# ATtiny2313 device description
Architecture: AVR8; Family: tinyAVR
Programming and debug interfaces: ISP, HVPP, debugWIRE
Registers are 8-bit, access not given, no defined reset value unless marked. A register's access mark holds for its fields unless they carry their own. Offsets are from the block's base; lines under a group give offsets from that group; [hi:lo] are bit positions; {n}, {i} and the like mark numbered series; 'fields as' and 'values as' point back to an identical list; <NAME> marks a mode.

## Ordering variants
ATtiny2313V-10PU: PDIP20, up to 10 MHz, -40 to 85 C, 1.8 to 5.5 V
ATtiny2313V-10SU, ATtiny2313V-10SUR: SOIC20, up to 10 MHz, -40 to 85 C, 1.8 to 5.5 V
ATtiny2313V-10MU, ATtiny2313V-10MUR: MLF20, up to 10 MHz, -40 to 85 C, 1.8 to 5.5 V
ATtiny2313-20PU: PDIP20, up to 20 MHz, -40 to 85 C, 2.7 to 5.5 V
ATtiny2313-20SU, ATtiny2313-20SUR: SOIC20, up to 20 MHz, -40 to 85 C, 2.7 to 5.5 V
ATtiny2313-20MU, ATtiny2313-20MUR: MLF20, up to 20 MHz, -40 to 85 C, 2.7 to 5.5 V

## Memory
prog space: start 0x0000 size 0x0800, little endian
  0x0000 FLASH size 0x0800 flash, rw, executable, page 0x20
signatures space: start 0 size 3, little endian
  0 SIGNATURES size 3 signatures, ro
fuses space: start 0 size 0x0003, little endian
  0 FUSES size 0x0003 fuses, rw
lockbits space: start 0 size 0x0001, little endian
  0 LOCKBITS size 0x0001 lockbits, rw
data space: start 0x0000 size 0x00e0, little endian
  0x0000 REGISTERS size 0x0020 regs
  0x0020 MAPPED_IO size 0x0040 io
  0x0060 IRAM size 0x0080 ram
eeprom space: start 0x0000 size 0x0080, little endian
  0x0000 EEPROM size 0x0080 eeprom, rw, page 0x04
io space: start 0x00 size 0x40, little endian
osccal space: start 0 size 2, little endian
  0 OSCCAL size 2 osccal, ro

## Peripheral instances (address, pins/pin function, parameters)
PORTB at 0x00 — I/O Port
PORTD at 0x00 — I/O Port
PORTA at 0x00 — I/O Port
TC0 at 0x00 — Timer/Counter, 8-bit
TC1 at 0x00 — Timer/Counter, 16-bit
WDT at 0x00 — Watchdog Timer
EXINT at 0x00 — External Interrupts
USART at 0x00
AC at 0x00 — Analog Comparator
EEPROM at 0x00
CPU at 0x00 — CPU Registers
  parameters: CORE_VERSION=V2, NEW_INSTRUCTIONS=lpm rd,z+
USI at 0x00 — Universal Serial Interface
FUSE at 0 in fuses — Fuses
LOCKBIT at 0 in lockbits — Lockbits

## Interrupts
0 RESET — External Reset, Power-on Reset and Watchdog Reset
1 INT0 — External Interrupt Request 0
2 INT1 — External Interrupt Request 1
3 TIMER1_CAPT — Timer/Counter1 Capture Event
4 TIMER1_COMPA — Timer/Counter1 Compare Match A
5 TIMER1_OVF — Timer/Counter1 Overflow
6 TIMER0_OVF — Timer/Counter0 Overflow
7 USART_RX — USART, Rx Complete
8 USART_UDRE — USART Data Register Empty
9 USART_TX — USART, Tx Complete
10 ANA_COMP — Analog Comparator
11 PCINT
12 TIMER1_COMPB
13 TIMER0_COMPA
14 TIMER0_COMPB
15 USI_START — USI Start Condition
16 USI_OVERFLOW
17 EEPROM_Ready
18 WDT_OVERFLOW — Watchdog Timer Overflow

## Properties
SIGNATURES: JTAGID=0x910A, SIGNATURE0=0x1e, SIGNATURE1=0x91, SIGNATURE2=0x0a
OCD: OCD_REVISION=0, OCD_DATAREG=0x1f, PROGBASE=0x0000

## LOCKBIT — Lockbits
Instances: LOCKBIT 0 in lockbits
0x00 LOCKBIT reset 0xFF
  [1:0] LB — Memory Lock
    0=PROG_VER_DISABLED (Further programming and verification disabled); 2=PROG_DISABLED (Further programming disabled); 3=NO_LOCK (No memory lock features enabled)

## PORTB — I/O Port
Instances: PORTB 0x00
0x36 PINB — Port B Input Pins
0x37 DDRB — Port B Data Direction Register
0x38 PORTB — Port B Data Register

## PORTD — I/O Port
Instances: PORTD 0x00
0x30 PIND bits used 6:0 — Input Pins, Port D
0x31 DDRD bits used 6:0 — Data Direction Register, Port D
0x32 PORTD bits used 6:0 — Data Register, Port D

## PORTA — I/O Port
Instances: PORTA 0x00
0x39 PINA bits used 2:0 — Port A Input Pins
0x3A DDRA bits used 2:0 — Port A Data Direction Register
0x3B PORTA bits used 2:0 — Port A Data Register

## TC0 (TC8 module) — Timer/Counter, 8-bit
Instances: TC0 0x00
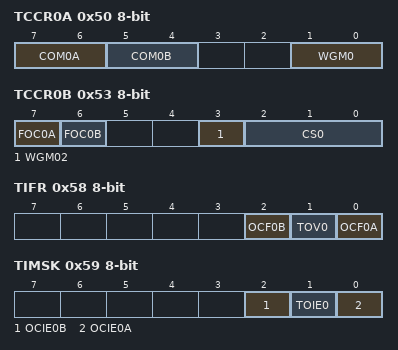
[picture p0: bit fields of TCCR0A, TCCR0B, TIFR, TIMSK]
0x50 TCCR0A — Timer/Counter Control Register A
  [7:6] COM0A — Compare Match Output A Mode
  [5:4] COM0B — Compare Match Output B Mode
  [1:0] WGM0 — Waveform Generation Mode
0x52 TCNT0 — Timer/Counter0
0x53 TCCR0B — Timer/Counter Control Register B
  [7] FOC0A — Force Output Compare B
  [6] FOC0B — Force Output Compare B
  [3] WGM02
  [2:0] CS0 — Clock Select
    0=NO_CLOCK_SOURCE_STOPPED; 1=RUNNING_NO_PRESCALING; 2=RUNNING_CLK_8; 3=RUNNING_CLK_64; 4=RUNNING_CLK_256; 5=RUNNING_CLK_1024; 6=RUNNING_EXTCLK_TN_FALLING_EDGE; 7=RUNNING_EXTCLK_TN_RISING_EDGE
0x56 OCR0A — Timer/Counter0 Output Compare Register
0x58 TIFR — Timer/Counter Interrupt Flag register
  [2] OCF0B — Timer/Counter0 Output Compare Flag 0B
  [1] TOV0 — Timer/Counter0 Overflow Flag
  [0] OCF0A — Timer/Counter0 Output Compare Flag 0A
0x59 TIMSK — Timer/Counter Interrupt Mask Register
  [2] OCIE0B — Timer/Counter0 Output Compare Match B Interrupt Enable
  [1] TOIE0 — Timer/Counter0 Overflow Interrupt Enable
  [0] OCIE0A — Timer/Counter0 Output Compare Match A Interrupt Enable
0x5C OCR0B — Timer/Counter0 Output Compare Register
